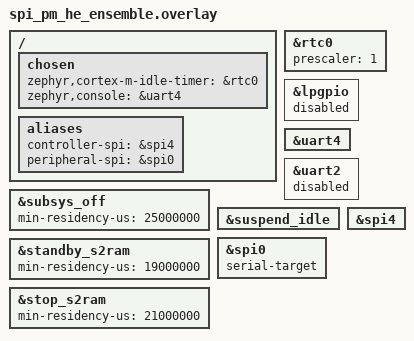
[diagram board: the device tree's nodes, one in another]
/* Copyright (C) Alif Semiconductor - All Rights Reserved.
 * Use, distribution and modification of this code is permitted under the
 * terms stated in the Alif Semiconductor Software License Agreement
 *
 * You should have received a copy of the Alif Semiconductor Software
 * License Agreement with this file. If not, please write to:
 * contact@alifsemi.com, or visit: https://alifsemi.com/license
 *
 * For SPI controller CS as:
 * - H/W controlled (default):
 *   - use CS pinmux as H/W
 *     - example for LPSPI (spi4) as controller "PIN_P7_7__LPSPI_SS_A"
 *  "OR"
 * - S/W controlled using gpio:
 *   - use CS pinmux as gpio
 *     - example for LPSPI (spi4) as controller "PIN_P7_7__GPIO"
 *   - define cs-gpios property
 *     - example for LPSPI (spi4) as controller
 *        cs-gpios = <&gpio7 7 GPIO_ACTIVE_LOW>;
 */

&rtc0 {
	prescaler = <1>;
	status = "okay";
};

&lpgpio {
	status = "disabled";
};

&uart4 {
	status = "okay";
};

&uart2 {
	status = "disabled";
};

&subsys_off {
	min-residency-us = <25000000>;
	status = "okay";
};

&standby_s2ram {
	min-residency-us = <19000000>;
	status = "okay";
};

&stop_s2ram {
	min-residency-us = <21000000>;
	status = "okay";
};

&suspend_idle {
	status = "okay";
};

/ {
	chosen {
		zephyr,cortex-m-idle-timer = &rtc0;
		zephyr,console = &uart4;
	};
};

/* default SPI controller CS is H/W controlled,
 * enable this to use as S/W controlled using gpio.
 */
#define SPI_CONTROLLER_CS_SW_CONTROLLED_GPIO 0

/ {
	aliases {
		controller-spi = &spi4;
		peripheral-spi = &spi0;
	};
};

&spi4 {
	status = "okay";

#if SPI_CONTROLLER_CS_SW_CONTROLLED_GPIO
	cs-gpios = <&gpio7 7 GPIO_ACTIVE_LOW>;
	/* as we are testing Loopback on the same board,
	 * make sure controller interrupt priority is
	 * higher than peripheral interrupt priority.
	 */
	interrupts = <46 0>;
#endif /* SPI_CONTROLLER_CS_SW_CONTROLLED_GPIO */
};

#if SPI_CONTROLLER_CS_SW_CONTROLLED_GPIO
/* use SPI controller CS pinmux as gpio. */
&pinctrl_lpspi {
	group0 {
		pinmux = < PIN_P7_4__LPSPI_MISO_A >,
			 < PIN_P7_5__LPSPI_MOSI_A >,
			 < PIN_P7_6__LPSPI_SCLK_A >,
			 < PIN_P7_7__GPIO >;
		read-enable = < 0x1 >;
	};
};

&gpio7 {
	status = "okay";
};
#endif /* SPI_CONTROLLER_CS_SW_CONTROLLED_GPIO */

&spi0 {
	status = "okay";
	serial-target;

#if SPI_CONTROLLER_CS_SW_CONTROLLED_GPIO
	interrupts = <137 1>;
#endif
};
